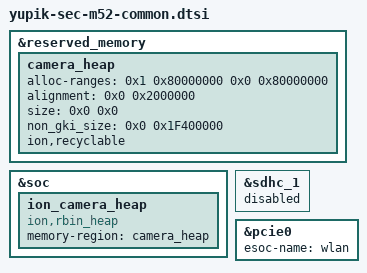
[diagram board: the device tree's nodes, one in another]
/* Copyright (c) 2021, The Linux Foundation. All rights reserved.
 *
 * This program is free software; you can redistribute it and/or modify
 * it under the terms of the GNU General Public License version 2 and
 * only version 2 as published by the Free Software Foundation.
 *
 * This program is distributed in the hope that it will be useful,
 * but WITHOUT ANY WARRANTY; without even the implied warranty of
 * MERCHANTABILITY or FITNESS FOR A PARTICULAR PURPOSE.  See the
 * GNU General Public License for more details.
 */

&reserved_memory {
	camera_heap: camera_heap {
		alloc-ranges = <0x1 0x80000000 0x0 0x80000000>;
		alignment = <0x0 0x2000000>;
		size = <0x0 0x0>;
		non_gki_size = <0x0 0x1F400000>;
		ion,recyclable;
	};
};

&soc {
	ion_camera_heap {
		compatible = "ion,rbin_heap";
		memory-region = <&camera_heap>;
	};
};

&sdhc_1 {                                                                        
	status = "disabled";                                                     
};

&pcie0 {
	esoc-name = "wlan";
};
